# PIC32MX470F512H register map
Registers are 32-bit, access not given, reset 0x0 unless marked. A register's access mark holds for its fields unless they carry their own. Offsets are from the block's base; [hi:lo] are bit positions; {n}, {i} and the like mark numbered series; 'fields as' and 'values as' point back to an identical list.

## UART1 — UART1 peripheral
Base 0xBF806000
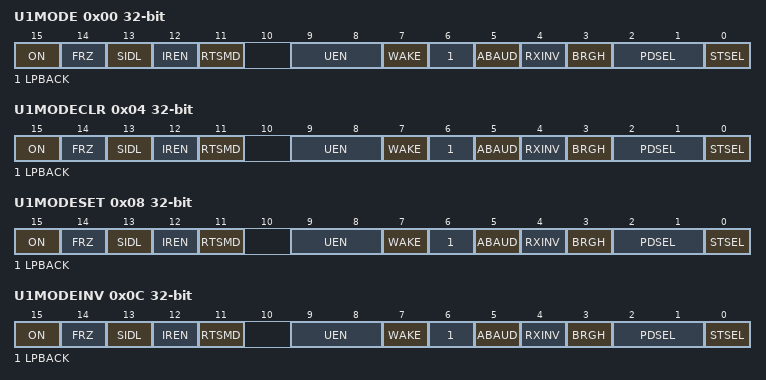
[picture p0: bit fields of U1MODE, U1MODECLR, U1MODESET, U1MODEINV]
0x00 U1MODE
  [15] ON, [14] FRZ, [13] SIDL, [12] IREN, [11] RTSMD, [9:8] UEN, [7] WAKE, [6] LPBACK, [5] ABAUD, [4] RXINV, [3] BRGH, [2:1] PDSEL, [0] STSEL
0x04 U1MODECLR
  fields as U1MODE
0x08 U1MODESET
  fields as U1MODE
0x0C U1MODEINV
  fields as U1MODE
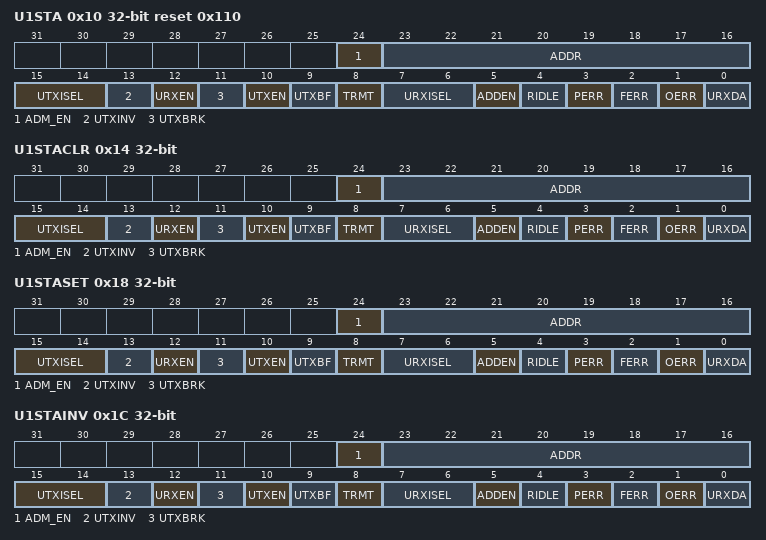
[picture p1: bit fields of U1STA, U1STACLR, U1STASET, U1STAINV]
0x10 U1STA reset 0x110
  [24] ADM_EN, [23:16] ADDR, [15:14] UTXISEL, [13] UTXINV, [12] URXEN, [11] UTXBRK, [10] UTXEN, [9] UTXBF, [8] TRMT, [7:6] URXISEL, [5] ADDEN, [4] RIDLE, [3] PERR, [2] FERR, [1] OERR, [0] URXDA
0x14 U1STACLR
  fields as U1STA
0x18 U1STASET
  fields as U1STA
0x1C U1STAINV
  fields as U1STA
0x20 U1TXREG
  [8:0] U1TXREG
0x30 U1RXREG
  [8:0] U1RXREG
0x40 U1BRG
  [15:0] BRG
0x44 U1BRGCLR
  [15:0] BRG
0x48 U1BRGSET
  [15:0] BRG
0x4C U1BRGINV
  [15:0] BRG

## UART2 — UART2 peripheral
Base 0xBF806200
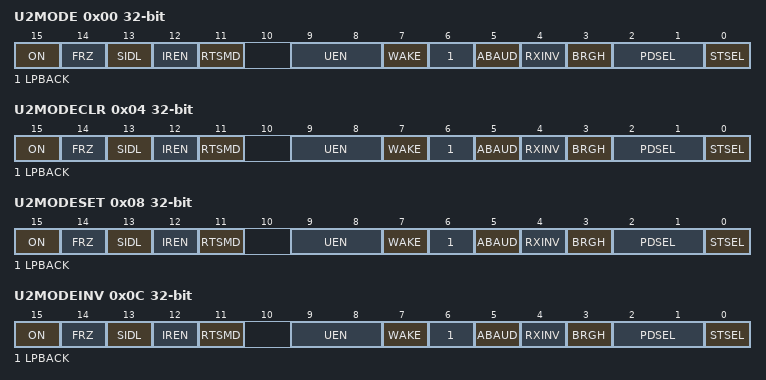
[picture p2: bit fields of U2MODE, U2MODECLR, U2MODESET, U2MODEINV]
0x00 U2MODE
  [15] ON, [14] FRZ, [13] SIDL, [12] IREN, [11] RTSMD, [9:8] UEN, [7] WAKE, [6] LPBACK, [5] ABAUD, [4] RXINV, [3] BRGH, [2:1] PDSEL, [0] STSEL
0x04 U2MODECLR
  fields as U2MODE
0x08 U2MODESET
  fields as U2MODE
0x0C U2MODEINV
  fields as U2MODE
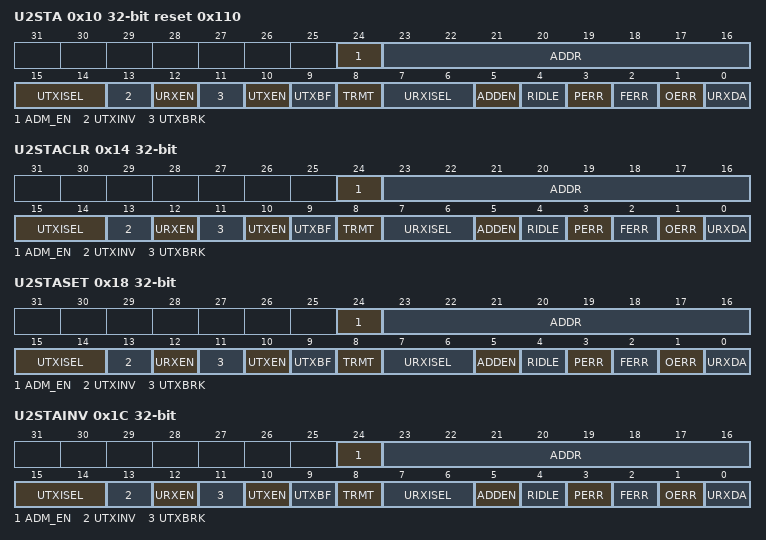
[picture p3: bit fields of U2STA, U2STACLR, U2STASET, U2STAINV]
0x10 U2STA reset 0x110
  [24] ADM_EN, [23:16] ADDR, [15:14] UTXISEL, [13] UTXINV, [12] URXEN, [11] UTXBRK, [10] UTXEN, [9] UTXBF, [8] TRMT, [7:6] URXISEL, [5] ADDEN, [4] RIDLE, [3] PERR, [2] FERR, [1] OERR, [0] URXDA
0x14 U2STACLR
  fields as U2STA
0x18 U2STASET
  fields as U2STA
0x1C U2STAINV
  fields as U2STA
0x20 U2TXREG
  [8:0] U2TXREG
0x30 U2RXREG
  [8:0] U2RXREG
0x40 U2BRG
  [15:0] BRG
0x44 U2BRGCLR
  [15:0] BRG
0x48 U2BRGSET
  [15:0] BRG
0x4C U2BRGINV
  [15:0] BRG

## UART3 — UART3 peripheral
Base 0xBF806400
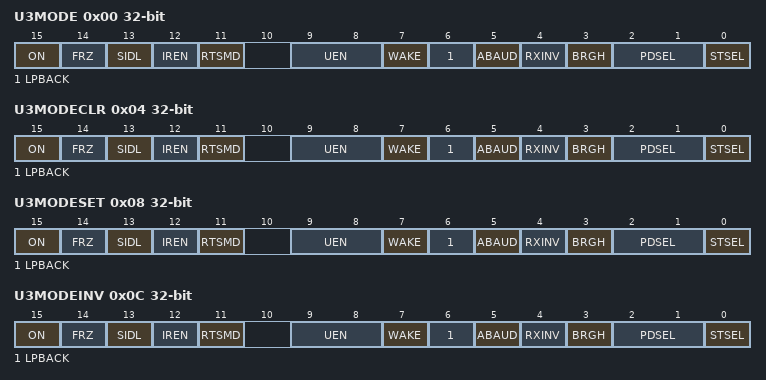
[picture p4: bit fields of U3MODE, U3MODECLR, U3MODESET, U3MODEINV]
0x00 U3MODE
  [15] ON, [14] FRZ, [13] SIDL, [12] IREN, [11] RTSMD, [9:8] UEN, [7] WAKE, [6] LPBACK, [5] ABAUD, [4] RXINV, [3] BRGH, [2:1] PDSEL, [0] STSEL
0x04 U3MODECLR
  fields as U3MODE
0x08 U3MODESET
  fields as U3MODE
0x0C U3MODEINV
  fields as U3MODE
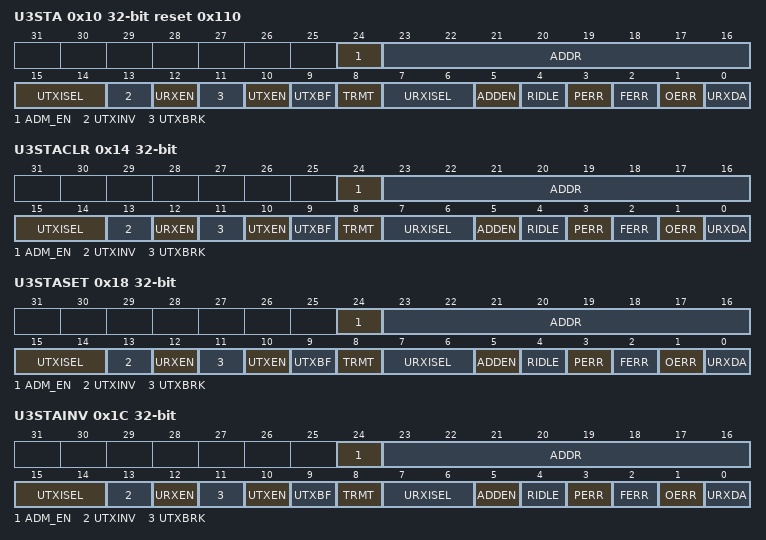
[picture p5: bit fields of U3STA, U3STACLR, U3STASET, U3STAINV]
0x10 U3STA reset 0x110
  [24] ADM_EN, [23:16] ADDR, [15:14] UTXISEL, [13] UTXINV, [12] URXEN, [11] UTXBRK, [10] UTXEN, [9] UTXBF, [8] TRMT, [7:6] URXISEL, [5] ADDEN, [4] RIDLE, [3] PERR, [2] FERR, [1] OERR, [0] URXDA
0x14 U3STACLR
  fields as U3STA
0x18 U3STASET
  fields as U3STA
0x1C U3STAINV
  fields as U3STA
0x20 U3TXREG
  [8:0] U3TXREG
0x30 U3RXREG
  [8:0] U3RXREG
0x40 U3BRG
  [15:0] BRG
0x44 U3BRGCLR
  [15:0] BRG
0x48 U3BRGSET
  [15:0] BRG
0x4C U3BRGINV
  [15:0] BRG

## UART4 — UART4 peripheral
Base 0xBF806600
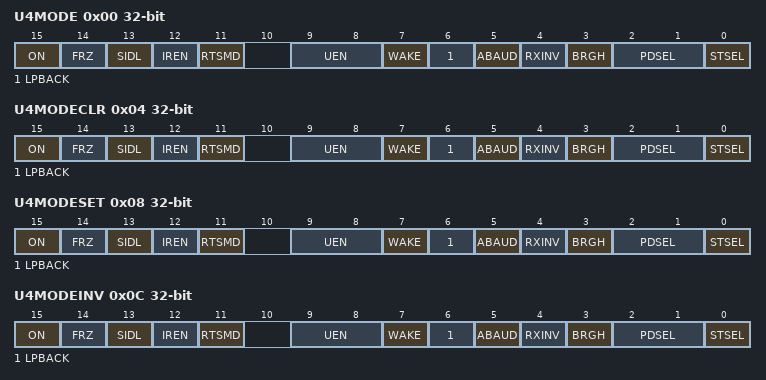
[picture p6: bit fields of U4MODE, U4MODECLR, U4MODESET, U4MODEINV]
0x00 U4MODE
  [15] ON, [14] FRZ, [13] SIDL, [12] IREN, [11] RTSMD, [9:8] UEN, [7] WAKE, [6] LPBACK, [5] ABAUD, [4] RXINV, [3] BRGH, [2:1] PDSEL, [0] STSEL
0x04 U4MODECLR
  fields as U4MODE
0x08 U4MODESET
  fields as U4MODE
0x0C U4MODEINV
  fields as U4MODE
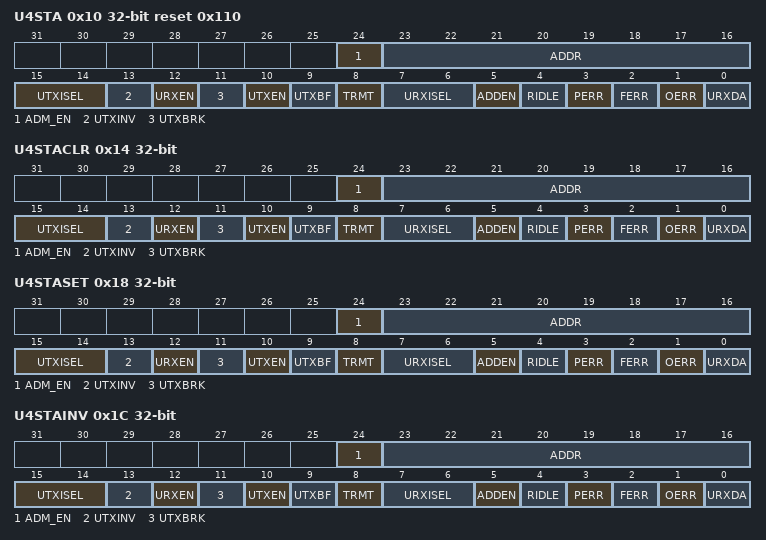
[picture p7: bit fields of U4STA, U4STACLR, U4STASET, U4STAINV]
0x10 U4STA reset 0x110
  [24] ADM_EN, [23:16] ADDR, [15:14] UTXISEL, [13] UTXINV, [12] URXEN, [11] UTXBRK, [10] UTXEN, [9] UTXBF, [8] TRMT, [7:6] URXISEL, [5] ADDEN, [4] RIDLE, [3] PERR, [2] FERR, [1] OERR, [0] URXDA
0x14 U4STACLR
  fields as U4STA
0x18 U4STASET
  fields as U4STA
0x1C U4STAINV
  fields as U4STA
0x20 U4TXREG
  [8:0] U4TXREG
0x30 U4RXREG
  [8:0] U4RXREG
0x40 U4BRG
  [15:0] BRG
0x44 U4BRGCLR
  [15:0] BRG
0x48 U4BRGSET
  [15:0] BRG
0x4C U4BRGINV
  [15:0] BRG

## PMP — PMP peripheral
Base 0xBF807000
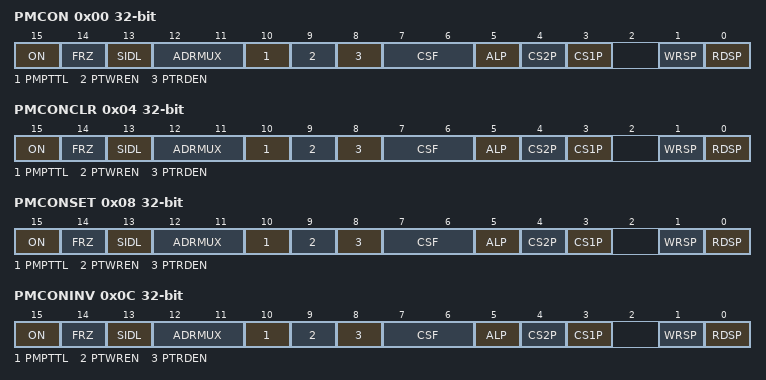
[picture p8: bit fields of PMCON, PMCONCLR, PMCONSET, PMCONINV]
0x00 PMCON
  [15] ON, [14] FRZ, [13] SIDL, [12:11] ADRMUX, [10] PMPTTL, [9] PTWREN, [8] PTRDEN, [7:6] CSF, [5] ALP, [4] CS2P, [3] CS1P, [1] WRSP, [0] RDSP
0x04 PMCONCLR
  fields as PMCON
0x08 PMCONSET
  fields as PMCON
0x0C PMCONINV
  fields as PMCON
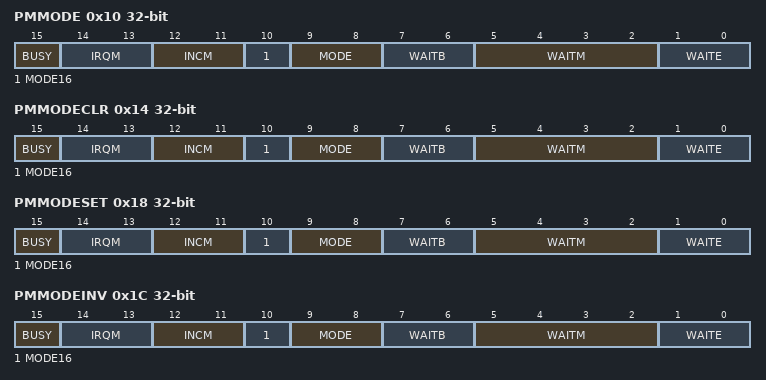
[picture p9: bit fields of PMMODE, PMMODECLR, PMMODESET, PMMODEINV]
0x10 PMMODE
  [15] BUSY, [14:13] IRQM, [12:11] INCM, [10] MODE16, [9:8] MODE, [7:6] WAITB, [5:2] WAITM, [1:0] WAITE
0x14 PMMODECLR
  fields as PMMODE
0x18 PMMODESET
  fields as PMMODE
0x1C PMMODEINV
  fields as PMMODE
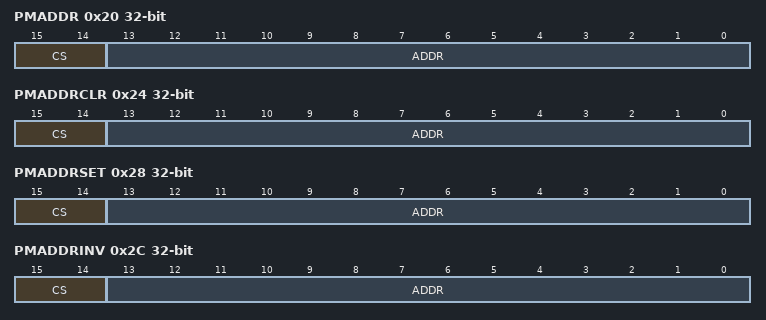
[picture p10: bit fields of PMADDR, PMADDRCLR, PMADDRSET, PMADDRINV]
0x20 PMADDR
  [15:14] CS, [13:0] ADDR
0x24 PMADDRCLR
  [15:14] CS, [13:0] ADDR
0x28 PMADDRSET
  [15:14] CS, [13:0] ADDR
0x2C PMADDRINV
  [15:14] CS, [13:0] ADDR
0x30 PMDOUT
  [31:0] DATAOUT
0x34 PMDOUTCLR
  [31:0] DATAOUT
0x38 PMDOUTSET
  [31:0] DATAOUT
0x3C PMDOUTINV
  [31:0] DATAOUT
0x40 PMDIN
  [31:0] DATAIN
0x44 PMDINCLR
  [31:0] DATAIN
0x48 PMDINSET
  [31:0] DATAIN
0x4C PMDININV
  [31:0] DATAIN
0x50 PMAEN
  [15:0] PTEN
0x54 PMAENCLR
  [15:0] PTEN
0x58 PMAENSET
  [15:0] PTEN
0x5C PMAENINV
  [15:0] PTEN
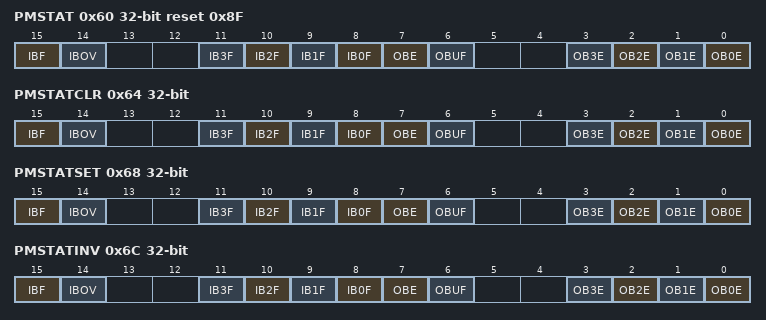
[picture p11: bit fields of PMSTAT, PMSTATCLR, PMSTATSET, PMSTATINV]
0x60 PMSTAT reset 0x8F
  [15] IBF, [14] IBOV, [n+8] IB{n}F (n=0..3), [7] OBE, [6] OBUF, [n] OB{n}E (n=0..3)
0x64 PMSTATCLR
  fields as PMSTAT
0x68 PMSTATSET
  fields as PMSTAT
0x6C PMSTATINV
  fields as PMSTAT
